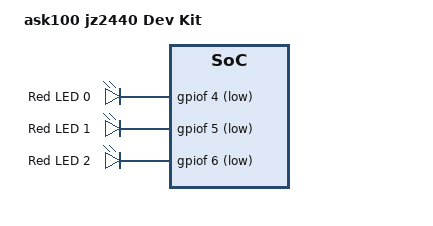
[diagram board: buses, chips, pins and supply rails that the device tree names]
/*
 * Copyright (c) 2017 Shawn Nock <shawn@monadnock.ca>
 * Copyright (c) 2017 Linaro Limited
 *
 * SPDX-License-Identifier: Apache-2.0
 */

/dts-v1/;
#include <samsung/s3c2440.dtsi>

/ {
	model = "ask100 jz2440 Dev Kit";
	compatible = "ask100,jz2440";

	aliases {
		led0 = &led0;
		led1 = &led1;
		led2 = &led2;
	};

	leds {
		compatible = "gpio-leds";
		led0: led_0 {
			gpios = <&gpiof 4 GPIO_INT_ACTIVE_LOW>;
			label = "Red LED 0";
		};

		led1: led_1 {
			gpios = <&gpiof 5 GPIO_INT_ACTIVE_LOW>;
			label = "Red LED 1";
		};

		led2: led_2 {
			gpios = <&gpiof 6 GPIO_INT_ACTIVE_LOW>;
			label = "Red LED 2";
		};
		
	};
	
};

